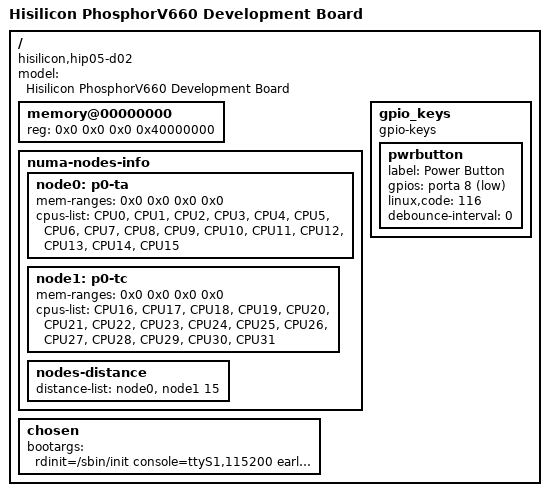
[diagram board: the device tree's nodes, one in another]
/**
 * dts file for Hisilicon PhosphorV660 EVB Board
 *
 * Copyright (C) 2014,2015 Hisilicon Ltd.
 *
 * This program is free software; you can redistribute it and/or modify
 * it under the terms of the GNU General Public License version 2 as
 * publishhed by the Free Software Foundation.
 *
/memreserve/ 0x00000000 0x00010000;
 */

/dts-v1/;

#include "hip06.dtsi"

/ {
	model = "Hisilicon PhosphorV660 Development Board";
	compatible = "hisilicon,hip05-d02", "hisilicon,hisi-pv660";

	memory@00000000 {
		device_type = "memory";
		reg = <0x0 0x0 0x0 0x40000000>;
	};

	numa-nodes-info {
		node0: p0-ta {
			mem-ranges = <0x0 0x0 0x0 0x0>;
			cpus-list = <&CPU0 &CPU1 &CPU2 &CPU3>,
				    <&CPU4 &CPU5 &CPU6 &CPU7>,
				    <&CPU8 &CPU9 &CPU10 &CPU11>,
				    <&CPU12 &CPU13 &CPU14 &CPU15>;
		};

		node1: p0-tc {
			mem-ranges = <0x0 0x0 0x0 0x0>;
			cpus-list = <&CPU16 &CPU17 &CPU18 &CPU19>,
				    <&CPU20 &CPU21 &CPU22 &CPU23>,
				    <&CPU24 &CPU25 &CPU26 &CPU27>,
				    <&CPU28 &CPU29 &CPU30 &CPU31>;
		};

		nodes-distance {
			distance-list = <&node0 &node1 15>;
		};
	};
/*
	reserved-memory {
		#address-cells = <0x2>;
		#size-cells = <0x2>;
		ranges;

		P0_L3_Directory {
			status = "ok";
			reg = <0x017 0xfe000000 0x0 0x2000000>, <0x01f 0xfe000000 0x0 0x2000000>;
		};
	};
*/
	chosen {
		bootargs = "rdinit=/sbin/init console=ttyS1,115200 earlycon=hisilpcuart,mmio,0xa01b0000,0,0x2f8 initrd=0x7000000,500M pci=pcie_bus_perf";
	};

	gpio_keys {
		compatible = "gpio-keys";
		#address-cells = <1>;
		#size-cells = <0>;

		pwrbutton {
			label = "Power Button";
			gpios = <&porta 8 1>;
			linux,code = <116>;
			debounce-interval = <0>;
		};
	};
};
